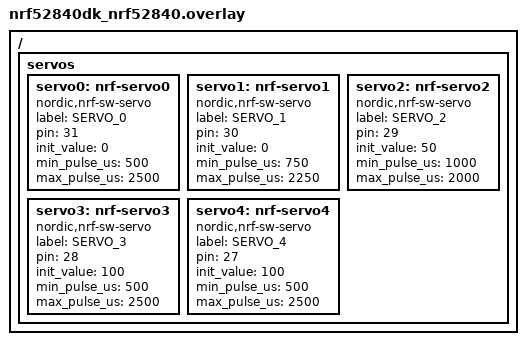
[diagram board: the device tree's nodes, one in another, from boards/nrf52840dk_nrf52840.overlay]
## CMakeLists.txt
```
# SPDX-License-Identifier: Apache-2.0

cmake_minimum_required(VERSION 3.13.1)

find_package(Zephyr REQUIRED HINTS $ENV{ZEPHYR_BASE})
project(servo)

FILE(GLOB app_sources src/*.c)
target_sources(app PRIVATE ${app_sources})
```

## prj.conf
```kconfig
# Logging
CONFIG_USE_SEGGER_RTT=y
CONFIG_RTT_CONSOLE=n
CONFIG_UART_CONSOLE=n
CONFIG_CONSOLE=n
CONFIG_STDOUT_CONSOLE=n
CONFIG_PRINTK=n
CONFIG_EARLY_CONSOLE=n

# Drivers and peripherals
CONFIG_I2C=n
CONFIG_WATCHDOG=n
CONFIG_PINMUX=n
CONFIG_SPI=n
CONFIG_SERIAL=n
CONFIG_NFCT_PINS_AS_GPIOS=y

# Power management
CONFIG_SYS_POWER_MANAGEMENT=y

# Interrupts
CONFIG_DYNAMIC_INTERRUPTS=n
CONFIG_IRQ_OFFLOAD=n

# Memory protection
CONFIG_THREAD_CUSTOM_DATA=n
CONFIG_FPU=n

# Boot
CONFIG_BOOT_BANNER=n
CONFIG_BOOT_DELAY=0

# Unneeded features
CONFIG_TIMESLICING=n
CONFIG_MINIMAL_LIBC_MALLOC=n

# Drivers
CONFIG_NRF_SW_SERVO=y
CONFIG_NRF_SW_SERVO_ALLOW_PWM0=y
CONFIG_NRF_SW_SERVO_ALLOW_PWM1=y
CONFIG_NRF_SW_SERVO_ALLOW_PWM2=n
CONFIG_NRF_SW_SERVO_ALLOW_PWM3=n
CONFIG_GPIO=y

# Build
CONFIG_ASSERT=n
CONFIG_SIZE_OPTIMIZATIONS=y
CONFIG_LOG=y
CONFIG_DEBUG=y
```

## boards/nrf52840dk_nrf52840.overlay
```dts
/ {
    servos {
        servo0: nrf-servo0 {
            compatible = "nordic,nrf-sw-servo";
            label = "SERVO_0";
            pin = <31>;
            init_value = <0>;
            min_pulse_us = <500>;
            max_pulse_us = <2500>;
            status = "okay";
        };
		servo1: nrf-servo1 {
            compatible = "nordic,nrf-sw-servo";
            label = "SERVO_1";
            pin = <30>;
            init_value = <0>;
            min_pulse_us = <750>;
            max_pulse_us = <2250>;
            status = "okay";
        };
        servo2: nrf-servo2 {
            compatible = "nordic,nrf-sw-servo";
            label = "SERVO_2";
            pin = <29>;
            init_value = <50>;
            min_pulse_us = <1000>;
            max_pulse_us = <2000>;
            status = "okay";
        };
        servo3: nrf-servo3 {
            compatible = "nordic,nrf-sw-servo";
            label = "SERVO_3";
            pin = <28>;
            init_value = <100>;
            min_pulse_us = <500>;
            max_pulse_us = <2500>;
            status = "okay";
        };
        servo4: nrf-servo4 {
            compatible = "nordic,nrf-sw-servo";
            label = "SERVO_4";
            pin = <27>;
            init_value = <100>;
            min_pulse_us = <500>;
            max_pulse_us = <2500>;
            status = "okay";
        };
    };
};
```

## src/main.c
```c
/*
 * Copyright (c) 2020 Daniel Veilleux
 *
 * SPDX-License-Identifier: Apache-2.0
 */

#include <kernel.h>
#include <string.h>
#include <zephyr.h>
#include <device.h>
#include <stdio.h>
#include <sys/__assert.h>
#include <drivers/servo.h>

#include <logging/log.h>
LOG_MODULE_REGISTER(main, LOG_LEVEL_DBG);

K_TIMER_DEFINE(sync_timer, NULL, NULL);

void main(void)
{
    int ret;
    const struct device *dev;

    if (IS_ENABLED(CONFIG_LOG_BACKEND_RTT)) {
        /* Give RTT log time to be flushed before executing tests */
        k_sleep(K_MSEC(500));
    }

    size_t len = z_device_get_all_static(&dev);
    const struct device *dev_end = dev + len;
    while (dev < dev_end) {
        if (z_device_ready(dev)
            && (dev->name != NULL)
            && (strlen(dev->name) != 0)) {
            LOG_INF("Found device: %s", dev->name);
        }
        dev++;
    }

    dev = device_get_binding("SERVO_0");
    if (dev == NULL) {
        LOG_ERR("Failed to get dev binding");
        return;
    }
    LOG_INF("dev is %p, name is %s", dev, dev->name);

    int step=4;
    k_timer_start(&sync_timer, K_MSEC(0), K_MSEC(500));
    while (1) {
    	int value;

    	step = ((step + 1) % 8);
    	switch(step) {
    	case 1:
    		value = 25;
    		break;
    	case 2:
    		value = 50;
    		break;
    	case 3:
    		value = 75;
    		break;
    	case 4:
    		value = 100;
    		break;
        case 5:
            value = 75;
            break;
        case 6:
            value = 50;
            break;
        case 7:
            value = 25;
            break;
        default:
            value = 0;
            break;
    	}

    	ret = servo_write(dev, value);
    	if (ret) {
    		LOG_INF("servo_write failed: %d", ret);
    	}
    	k_timer_status_sync(&sync_timer);
    }
    LOG_INF("exiting");
}
```
